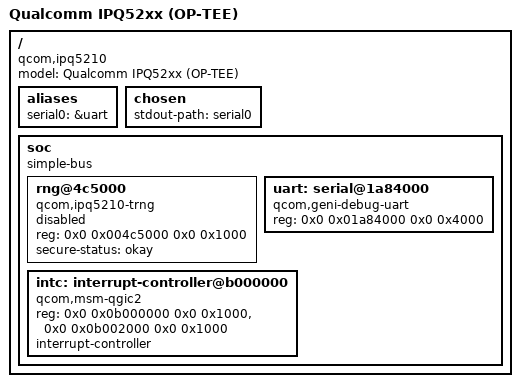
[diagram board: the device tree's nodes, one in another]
// SPDX-License-Identifier: BSD-3-Clause
/*
 * Copyright (c) Qualcomm Technologies, Inc. and/or its subsidiaries.
 *
 * Secure world view of IPQ52xx as seen by OP-TEE.
 *
 * Only the properties OP-TEE consumes are described, so properties such as
 * clocks, interrupts and pinctrl are left out. The compile-time values in
 * plat-qcom stay the fallback for every node.
 */

/dts-v1/;

/ {
	compatible = "qcom,ipq5210";
	model = "Qualcomm IPQ52xx (OP-TEE)";
	#address-cells = <2>;
	#size-cells = <2>;

	aliases {
		serial0 = &uart;
	};

	chosen {
		stdout-path = "serial0";
	};

	soc {
		compatible = "simple-bus";
		#address-cells = <2>;
		#size-cells = <2>;
		ranges;

		/* OP-TEE uses its own execution environment page of the TRNG */
		rng@4c5000 {
			compatible = "qcom,ipq5210-trng", "qcom,trng";
			reg = <0x0 0x004c5000 0x0 0x1000>;
			/* Only OP-TEE uses this page */
			status = "disabled";
			secure-status = "okay";
		};

		uart: serial@1a84000 {
			compatible = "qcom,geni-debug-uart";
			reg = <0x0 0x01a84000 0x0 0x4000>;
		};

		intc: interrupt-controller@b000000 {
			compatible = "qcom,msm-qgic2";
			reg = <0x0 0x0b000000 0x0 0x1000>,	/* GICD */
			      <0x0 0x0b002000 0x0 0x1000>;	/* GICC */
			interrupt-controller;
			#interrupt-cells = <3>;
		};
	};
};
